AUTOSAR XML (schema 4.0)
package /ADAS_Components
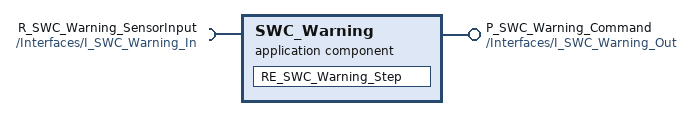
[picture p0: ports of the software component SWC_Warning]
  application sw component type SWC_Warning  # AUTOSAR Application SWC SWC_Warning for ADAS control
    provide port P_SWC_Warning_Command: provided-interface=/Interfaces/I_SWC_Warning_Out
    require port R_SWC_Warning_SensorInput: required-interface=/Interfaces/I_SWC_Warning_In
    behavior SWC_Warning_Behavior
      runnable RE_SWC_Warning_Step: symbol=SWC_Warning_Step
